# AT90USB162 register map
Vendor: Atmel; File version: 1.0
CPU: other r0p0, little endian, no MPU, no FPU, 4 interrupt priority bits
Registers are 8-bit, read-write, reset 0x0 unless marked. A register's access mark holds for its fields unless they carry their own. Offsets are from the block's base; [hi:lo] are bit positions; {n}, {i} and the like mark numbered series.

## EEPROM
Base 0x0000003F
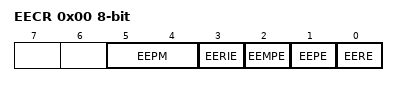
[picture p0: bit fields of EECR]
0x00 EECR — EEPROM Control Register
  [5:4] EEPM — EEPROM Programming Mode Bits
    0=Erase and Write in one operation; 1=Erase Only; 2=Write Only
  [3] EERIE — EEPROM Ready Interrupt Enable
  [2] EEMPE — EEPROM Master Write Enable
  [1] EEPE — EEPROM Write Enable
  [0] EERE — EEPROM Read Enable
0x01 EEDR — EEPROM Data Register
0x02 EEAR 16-bit (reset mask 0xFF) — EEPROM Address Register Low Bytes

## EXINT — External Interrupts
Base 0x0000003B
0x00 PCIFR — Pin Change Interrupt Flag Register
  [1:0] PCIF — Pin Change Interrupt Flags
0x01 EIFR — External Interrupt Flag Register
  [7:0] INTF — External Interrupt Flags
0x02 EIMSK — External Interrupt Mask Register
  [7:0] INT — External Interrupt Request 7 Enable
0x2D PCICR — Pin Change Interrupt Control Register
  [1:0] PCIE — Pin Change Interrupt Enables
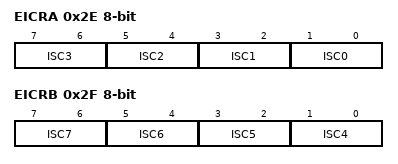
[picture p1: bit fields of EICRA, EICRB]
0x2E EICRA — External Interrupt Control Register A
  [2n+1:2n] ISC{n} (n=0..3) — External Interrupt Sense Control Bit
0x2F EICRB — External Interrupt Control Register B
  [2n-7:2n-8] ISC{n} (n=4..7) — External Interrupt 7-4 Sense Control Bit
0x30 PCMSK0 — Pin Change Mask Register 0
  [7:0] PCINT — Pin Change Enable Masks
0x31 PCMSK1 — Pin Change Mask Register 1
  [4:0] PCINT

## LOCKBIT — Lockbits
Base 0x00000000
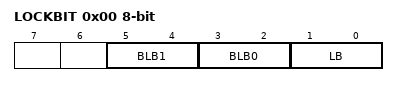
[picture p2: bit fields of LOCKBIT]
0x00 LOCKBIT
  [5:4] BLB1 — Boot Loader Protection Mode
    0=LPM_SPM_DISABLE (LPM and SPM prohibited in Boot Section); 1=LPM_DISABLE (LPM prohibited in Boot Section); 2=SPM_DISABLE (SPM prohibited in Boot Section); 3=NO_LOCK (No lock on SPM and LPM in Boot Section)
  [3:2] BLB0 — Boot Loader Protection Mode
    0=LPM_SPM_DISABLE (LPM and SPM prohibited in Application Section); 1=LPM_DISABLE (LPM prohibited in Application Section); 2=SPM_DISABLE (SPM prohibited in Application Section); 3=NO_LOCK (No lock on SPM and LPM in Application Section)
  [1:0] LB — Memory Lock
    0=PROG_VER_DISABLED (Further programming and verification disabled); 2=PROG_DISABLED (Further programming disabled); 3=NO_LOCK (No memory lock features enabled)

## PLL — Phase Locked Loop
Base 0x00000049
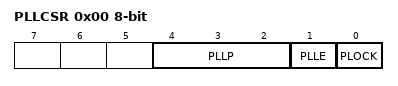
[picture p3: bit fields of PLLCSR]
0x00 PLLCSR — PLL Status and Control register
  [4:2] PLLP — PLL prescaler Bits
    3=Clock/4; 5=Clock/8
  [1] PLLE — PLL Enable Bit
  [0] PLOCK — PLL Lock Status Bit

## PORTB — I/O Port
Base 0x00000023
0x00 PINB — Port B Input Pins
0x01 DDRB — Port B Data Direction Register
0x02 PORTB — Port B Data Register

## PORTC — I/O Port
Base 0x00000026
0x00 PINC — Port C Input Pins
  [2:0] PINC — Port C Input Pins bits
0x01 DDRC — Port C Data Direction Register
  [2:0] DDC — Port C Data Direction Register bits
0x02 PORTC — Port C Data Register
  [2:0] PORTC — Port C Data Register bits

## PORTD — I/O Port
Base 0x00000029
0x00 PIND — Port D Input Pins
0x01 DDRD — Port D Data Direction Register
0x02 PORTD — Port D Data Register

## PS2 — PS/2 Controller
Base 0x000000FA
0x00 PS2CON — PS2 Pad Enable register
  [0] PS2EN — Enable
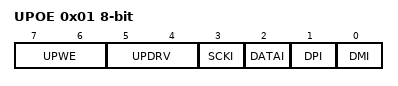
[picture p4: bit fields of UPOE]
0x01 UPOE
  [7:6] UPWE, [5:4] UPDRV, [3] SCKI, [2] DATAI, [1] DPI, [0] DMI

## SPI — Serial Peripheral Interface
Base 0x0000004C
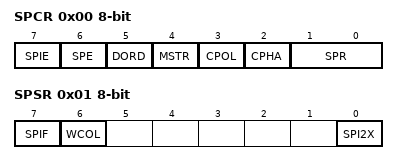
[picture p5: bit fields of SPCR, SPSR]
0x00 SPCR — SPI Control Register
  [7] SPIE — SPI Interrupt Enable
  [6] SPE — SPI Enable
  [5] DORD — Data Order
  [4] MSTR — Master/Slave Select
  [3] CPOL — Clock polarity
  [2] CPHA — Clock Phase
  [1:0] SPR — SPI Clock Rate Selects
    0=fosc/4; 1=fosc/16; 2=fosc/64; 3=fosc/128
0x01 SPSR — SPI Status Register
  [7] SPIF — SPI Interrupt Flag
  [6] WCOL — Write Collision Flag
  [0] SPI2X — Double SPI Speed Bit
0x02 SPDR — SPI Data Register

## TC0 — Timer/Counter, 8-bit
Base 0x00000035
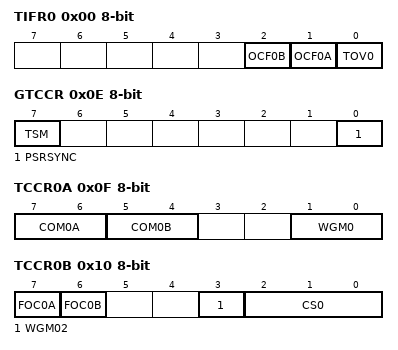
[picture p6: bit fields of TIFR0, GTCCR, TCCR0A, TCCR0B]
0x00 TIFR0 — Timer/Counter0 Interrupt Flag register
  [2] OCF0B — Timer/Counter0 Output Compare Flag 0B
  [1] OCF0A — Timer/Counter0 Output Compare Flag 0A
  [0] TOV0 — Timer/Counter0 Overflow Flag
0x0E GTCCR — General Timer/Counter Control Register
  [7] TSM — Timer/Counter Synchronization Mode
  [0] PSRSYNC — Prescaler Reset Timer/Counter1 and Timer/Counter0
0x0F TCCR0A — Timer/Counter Control Register A
  [7:6] COM0A — Compare Output Mode, Phase Correct PWM Mode
  [5:4] COM0B — Compare Output Mode, Fast PWm
  [1:0] WGM0 — Waveform Generation Mode
0x10 TCCR0B — Timer/Counter Control Register B
  [7] FOC0A — Force Output Compare A
  [6] FOC0B — Force Output Compare B
  [3] WGM02
  [2:0] CS0 — Clock Select
    0=No Clock Source (Stopped); 1=Running, No Prescaling; 2=Running, CLK/8; 3=Running, CLK/64; 4=Running, CLK/256; 5=Running, CLK/1024; 6=Running, ExtClk Tx Falling Edge; 7=Running, ExtClk Tx Rising Edge
0x11 TCNT0 — Timer/Counter0
0x12 OCR0A — Timer/Counter0 Output Compare Register
0x13 OCR0B — Timer/Counter0 Output Compare Register
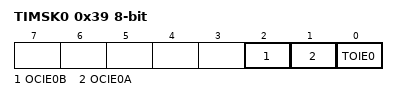
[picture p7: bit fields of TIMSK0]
0x39 TIMSK0 — Timer/Counter0 Interrupt Mask Register
  [2] OCIE0B — Timer/Counter0 Output Compare Match B Interrupt Enable
  [1] OCIE0A — Timer/Counter0 Output Compare Match A Interrupt Enable
  [0] TOIE0 — Timer/Counter0 Overflow Interrupt Enable
